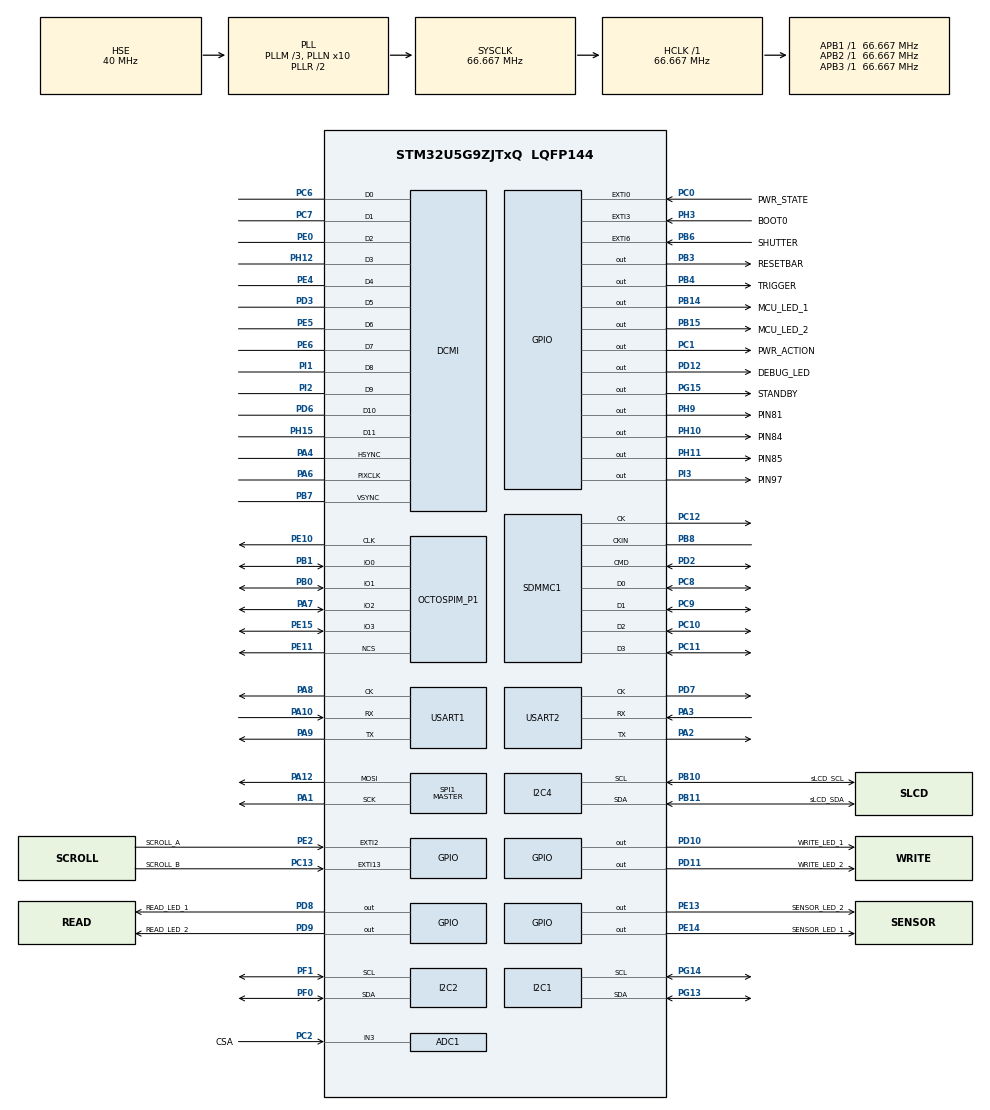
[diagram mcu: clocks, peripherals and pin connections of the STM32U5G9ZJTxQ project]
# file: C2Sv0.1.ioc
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ADC1.Channel-0\#ChannelRegularConversion=ADC_CHANNEL_3
ADC1.ContinuousConvMode=DISABLE
ADC1.MonitoredBy-0\#ChannelRegularConversion=__NULL
ADC1.NbrOfConversionFlag=1
ADC1.OffsetNumber-0\#ChannelRegularConversion=ADC_OFFSET_NONE
ADC1.Rank-0\#ChannelRegularConversion=1
ADC1.Resolution=ADC_RESOLUTION_14B
ADC1.SamplingTime-0\#ChannelRegularConversion=ADC_SAMPLETIME_5CYCLE
ADC1.master=1
CORTEX_M33_NS.userName=CORTEX_M33
DCMI.VSPolarity=DCMI_VSPOLARITY_HIGH
FILEX.FX_DRIVER_SDMMC_INIT=1
FILEX.FX_SD_INTERFACE=1
GPDMA1.IPHANDLE_GPDMACH11-SIMPLEREQUEST_GPDMACH11=__NULL
GPDMA1.PRIORITY_GPDMACH11=DMA_HIGH_PRIORITY
GPDMA1.RECAP_GPDMACH11=86
GPDMA1.REQUEST_GPDMACH11=GPDMA1_REQUEST_DCMI_PSSI
GPDMA1.SRCDATAWIDTH_GPDMACH11=DMA_SRC_DATAWIDTH_WORD
I2C1.Timing=0x108082C4
I2C2.Timing=0x108082C4
I2C4.Timing=0x108082C4
Mcu.Family=STM32U5
Mcu.Name=STM32U5G9ZJTxQ
Mcu.Package=LQFP144
NVIC.DCMI_PSSI_IRQn=true\:0\:0\:false\:false\:true\:true\:true\:true
NVIC.EXTI0_IRQn=true\:0\:0\:false\:false\:true\:true\:true\:true
NVIC.EXTI13_IRQn=true\:0\:0\:false\:false\:true\:true\:true\:true
NVIC.EXTI2_IRQn=true\:0\:0\:false\:false\:true\:true\:true\:true
NVIC.EXTI3_IRQn=true\:0\:0\:false\:false\:true\:true\:true\:true
NVIC.EXTI6_IRQn=true\:0\:0\:false\:false\:true\:true\:true\:true
NVIC.GPDMA1_Channel11_IRQn=true\:0\:0\:false\:false\:true\:false\:true\:true
NVIC.PriorityGroup=NVIC_PRIORITYGROUP_4
NVIC.SDMMC1_IRQn=true\:0\:0\:false\:false\:true\:true\:true\:true
OCTOSPI1.ChipSelectHighTime=3
OCTOSPI1.ClockPrescaler=5
OCTOSPI1.DeviceSize=24
OCTOSPI1.SampleShifting=HAL_OSPI_SAMPLE_SHIFTING_HALFCYCLE
PA1.Mode=TX_Only_Simplex_Unidirect_Master
PA1.Signal=SPI1_SCK
PA10.Mode=Synchronous
PA10.Signal=USART1_RX
PA12.Mode=TX_Only_Simplex_Unidirect_Master
PA12.Signal=SPI1_MOSI
PA13\ (JTMS/SWDIO).Mode=Serial_Wire
PA13\ (JTMS/SWDIO).Signal=DEBUG_JTMS-SWDIO
PA14\ (JTCK/SWCLK).Mode=Serial_Wire
PA14\ (JTCK/SWCLK).Signal=DEBUG_JTCK-SWCLK
PA2.Mode=Synchronous
PA2.Signal=USART2_TX
PA3.Mode=Synchronous
PA3.Signal=USART2_RX
PA4.GPIO_PuPd=GPIO_PULLDOWN
PA4.GPIO_Speed=GPIO_SPEED_FREQ_HIGH
PA4.Mode=Slave_12_bits_External_Synchro
PA4.Signal=DCMI_HSYNC
PA6.GPIO_PuPd=GPIO_PULLDOWN
PA6.GPIO_Speed=GPIO_SPEED_FREQ_HIGH
PA6.Mode=Slave_12_bits_External_Synchro
PA6.Signal=DCMI_PIXCLK
PA7.Mode=OCTOSPI1_IOL_Port1L
PA7.Signal=OCTOSPIM_P1_IO2
PA8.Mode=Synchronous
PA8.Signal=USART1_CK
PA9.Mode=Synchronous
PA9.Signal=USART1_TX
PB0.Mode=OCTOSPI1_IOL_Port1L
PB0.Signal=OCTOSPIM_P1_IO1
PB1.Mode=OCTOSPI1_IOL_Port1L
PB1.Signal=OCTOSPIM_P1_IO0
PB10.GPIO_Label=sLCD_SCL
PB10.Mode=I2C
PB10.Signal=I2C4_SCL
PB11.GPIO_Label=sLCD_SDA
PB11.Mode=I2C
PB11.Signal=I2C4_SDA
PB14.GPIO_Label=MCU_LED_1
PB14.Signal=GPIO_Output
PB15.GPIO_Label=MCU_LED_2
PB15.Signal=GPIO_Output
PB3\ (JTDO/TRACESWO).GPIO_Label=RESETBAR
PB3\ (JTDO/TRACESWO).GPIO_ModeDefaultOutputPP=GPIO_MODE_OUTPUT_OD
PB3\ (JTDO/TRACESWO).GPIO_PuPd=GPIO_NOPULL
PB3\ (JTDO/TRACESWO).PinState=GPIO_PIN_SET
PB3\ (JTDO/TRACESWO).Signal=GPIO_Output
PB4\ (NJTRST).GPIO_Label=TRIGGER
PB4\ (NJTRST).Signal=GPIO_Output
PB6.GPIO_Label=SHUTTER
PB6.GPIO_ModeDefaultEXTI=GPIO_MODE_IT_RISING_FALLING
PB6.Signal=GPXTI6
PB7.GPIO_PuPd=GPIO_PULLDOWN
PB7.GPIO_Speed=GPIO_SPEED_FREQ_HIGH
PB7.Mode=Slave_12_bits_External_Synchro
PB7.Signal=DCMI_VSYNC
PB8.GPIO_Speed_HighF_Default=GPIO_SPEED_FREQ_VERY_HIGH
PB8.Mode=SD_4_bits_Wide_bus_auto_dir_voltage_converter
PB8.Signal=SDMMC1_CKIN
PC0.GPIO_Label=PWR_STATE
PC0.GPIO_ModeDefaultEXTI=GPIO_MODE_IT_RISING
PC0.Signal=GPXTI0
PC1.GPIO_Label=PWR_ACTION
PC1.Signal=GPIO_Output
PC10.GPIO_Speed_HighF_Default=GPIO_SPEED_FREQ_VERY_HIGH
PC10.Mode=SD_4_bits_Wide_bus_auto_dir_voltage_converter
PC10.Signal=SDMMC1_D2
PC11.GPIO_Speed_HighF_Default=GPIO_SPEED_FREQ_VERY_HIGH
PC11.Mode=SD_4_bits_Wide_bus_auto_dir_voltage_converter
PC11.Signal=SDMMC1_D3
PC12.GPIO_Speed_HighF_Default=GPIO_SPEED_FREQ_VERY_HIGH
PC12.Mode=SD_4_bits_Wide_bus_auto_dir_voltage_converter
PC12.Signal=SDMMC1_CK
PC13.GPIO_Label=SCROLL_B
PC13.GPIO_ModeDefaultEXTI=GPIO_MODE_IT_RISING_FALLING
PC13.GPIO_PuPd=GPIO_PULLUP
PC13.Signal=GPXTI13
PC14-OSC32_IN\ (PC14).Mode=LSE-External-Clock-Source
PC14-OSC32_IN\ (PC14).Signal=RCC_OSC32_IN
PC2.GPIO_Label=CSA
PC2.GPIO_Pd=GPIO_PULLDOWN
PC2.Mode=IN3-Single-Ended
PC2.Signal=ADC1_IN3
PC6.GPIO_PuPd=GPIO_PULLDOWN
PC6.GPIO_Speed=GPIO_SPEED_FREQ_HIGH
PC6.Mode=Slave_12_bits_External_Synchro
PC6.Signal=DCMI_D0
PC7.GPIO_PuPd=GPIO_PULLDOWN
PC7.GPIO_Speed=GPIO_SPEED_FREQ_HIGH
PC7.Mode=Slave_12_bits_External_Synchro
PC7.Signal=DCMI_D1
PC8.GPIO_Speed_HighF_Default=GPIO_SPEED_FREQ_VERY_HIGH
PC8.Mode=SD_4_bits_Wide_bus_auto_dir_voltage_converter
PC8.Signal=SDMMC1_D0
PC9.GPIO_Speed_HighF_Default=GPIO_SPEED_FREQ_VERY_HIGH
PC9.Mode=SD_4_bits_Wide_bus_auto_dir_voltage_converter
PC9.Signal=SDMMC1_D1
PD10.GPIO_Label=WRITE_LED_1
PD10.Signal=GPIO_Output
PD11.GPIO_Label=WRITE_LED_2
PD11.Signal=GPIO_Output
PD12.GPIO_Label=DEBUG_LED
PD12.Signal=GPIO_Output
PD2.GPIO_Speed_HighF_Default=GPIO_SPEED_FREQ_VERY_HIGH
PD2.Mode=SD_4_bits_Wide_bus_auto_dir_voltage_converter
PD2.Signal=SDMMC1_CMD
PD3.GPIO_PuPd=GPIO_PULLDOWN
PD3.GPIO_Speed=GPIO_SPEED_FREQ_HIGH
PD3.Mode=Slave_12_bits_External_Synchro
PD3.Signal=DCMI_D5
PD6.GPIO_PuPd=GPIO_PULLDOWN
PD6.GPIO_Speed=GPIO_SPEED_FREQ_HIGH
PD6.Mode=Slave_12_bits_External_Synchro
PD6.Signal=DCMI_D10
PD7.Mode=Synchronous
PD7.Signal=USART2_CK
PD8.GPIO_Label=READ_LED_1
PD8.Signal=GPIO_Output
PD9.GPIO_Label=READ_LED_2
PD9.Signal=GPIO_Output
PE0.GPIO_PuPd=GPIO_PULLDOWN
PE0.GPIO_Speed=GPIO_SPEED_FREQ_HIGH
PE0.Mode=Slave_12_bits_External_Synchro
PE0.Signal=DCMI_D2
PE10.Mode=O1_P1_CLK
PE10.Signal=OCTOSPIM_P1_CLK
PE11.GPIO_PuPd=GPIO_PULLUP
PE11.Mode=OCTOSPI1_Port1_NCS
PE11.Signal=OCTOSPIM_P1_NCS
PE13.GPIO_Label=SENSOR_LED_2
PE13.Signal=GPIO_Output
PE14.GPIO_Label=SENSOR_LED_1
PE14.Signal=GPIO_Output
PE15.Mode=OCTOSPI1_IOL_Port1L
PE15.Signal=OCTOSPIM_P1_IO3
PE2.GPIO_Label=SCROLL_A
PE2.GPIO_ModeDefaultEXTI=GPIO_MODE_IT_RISING_FALLING
PE2.GPIO_PuPd=GPIO_PULLUP
PE2.Signal=GPXTI2
PE4.GPIO_PuPd=GPIO_PULLDOWN
PE4.GPIO_Speed=GPIO_SPEED_FREQ_HIGH
PE4.Mode=Slave_12_bits_External_Synchro
PE4.Signal=DCMI_D4
PE5.GPIO_PuPd=GPIO_PULLDOWN
PE5.GPIO_Speed=GPIO_SPEED_FREQ_HIGH
PE5.Mode=Slave_12_bits_External_Synchro
PE5.Signal=DCMI_D6
PE6.GPIO_PuPd=GPIO_PULLDOWN
PE6.GPIO_Speed=GPIO_SPEED_FREQ_HIGH
PE6.Mode=Slave_12_bits_External_Synchro
PE6.Signal=DCMI_D7
PF0.Mode=I2C
PF0.Signal=I2C2_SDA
PF1.Mode=I2C
PF1.Signal=I2C2_SCL
PG13.GPIO_Pu=GPIO_NOPULL
PG13.Mode=I2C
PG13.Signal=I2C1_SDA
PG14.Mode=I2C
PG14.Signal=I2C1_SCL
PG15.GPIO_Label=STANDBY
PG15.Signal=GPIO_Output
PH0-OSC_IN\ (PH0).Mode=HSE-External-Clock-Source
PH0-OSC_IN\ (PH0).Signal=RCC_OSC_IN
PH10.GPIO_Label=PIN84
PH10.Signal=GPIO_Output
PH11.GPIO_Label=PIN85
PH11.Signal=GPIO_Output
PH12.GPIO_PuPd=GPIO_PULLDOWN
PH12.GPIO_Speed=GPIO_SPEED_FREQ_HIGH
PH12.Mode=Slave_12_bits_External_Synchro
PH12.Signal=DCMI_D3
PH15.GPIO_PuPd=GPIO_PULLDOWN
PH15.GPIO_Speed=GPIO_SPEED_FREQ_HIGH
PH15.Mode=Slave_12_bits_External_Synchro
PH15.Signal=DCMI_D11
PH3-BOOT0.GPIO_Label=BOOT0
PH3-BOOT0.Signal=GPXTI3
PH9.GPIO_Label=PIN81
PH9.Signal=GPIO_Output
PI1.GPIO_PuPd=GPIO_PULLDOWN
PI1.GPIO_Speed=GPIO_SPEED_FREQ_HIGH
PI1.Mode=Slave_12_bits_External_Synchro
PI1.Signal=DCMI_D8
PI2.GPIO_PuPd=GPIO_PULLDOWN
PI2.GPIO_Speed=GPIO_SPEED_FREQ_HIGH
PI2.Mode=Slave_12_bits_External_Synchro
PI2.Signal=DCMI_D9
PI3.GPIO_Label=PIN97
PI3.Signal=GPIO_Output
ProjectManager.HeapSize=0x200
ProjectManager.StackSize=0x400
ProjectManager.TargetToolchain=STM32CubeIDE
RCC.ADCFreq_Value=16000000
RCC.AHBFreq_Value=66666666.66666667
RCC.APB1Freq_Value=66666666.66666667
RCC.APB1TimFreq_Value=66666666.66666667
RCC.APB2Freq_Value=66666666.66666667
RCC.APB2TimFreq_Value=66666666.66666667
RCC.APB3Freq_Value=66666666.66666667
RCC.CortexFreq_Value=66666666.66666667
RCC.EPOD_VALUE=40000000
RCC.HCLKFreq_Value=66666666.66666667
RCC.HSE_VALUE=40000000
RCC.HSI48_VALUE=48000000
RCC.HSI_VALUE=16000000
RCC.LSE_VALUE=32768
RCC.LSIDIV_VALUE=32000
RCC.MSI_VALUE=4000000
RCC.OCTOSPIMCLockSelection=RCC_OSPICLKSOURCE_PLL2
RCC.PLL1P=1
RCC.PLL2M=10
RCC.PLL2N=133
RCC.PLL2Q=4
RCC.PLL2Source=RCC_PLLSOURCE_HSE
RCC.PLLFRACN=0
RCC.PLLM=3
RCC.PLLN=10
RCC.PLLSourceVirtual=RCC_PLLSOURCE_HSE
RCC.RTCClockSelection=RCC_RTCCLKSOURCE_LSE
RCC.SDMMCClockSelection=RCC_SDMMCCLKSOURCE_CLK48
RCC.SYSCLKFreq_VALUE=66666666.66666667
RCC.SYSCLKSource=RCC_SYSCLKSOURCE_PLLCLK
RCC.VCOOutputFreq_Value=133333333.33333334
SDMMC1.ClockDiv=8
SPI1.CLKPhase=SPI_PHASE_2EDGE
SPI1.CLKPolarity=SPI_POLARITY_HIGH
SPI1.CalculateBaudRate=33.333332 MBits/s
SPI1.DataSize=SPI_DATASIZE_8BIT
SPI1.Direction=SPI_DIRECTION_2LINES_TXONLY
SPI1.Mode=SPI_MODE_MASTER
SPI1.VirtualType=VM_MASTER
USART1.VirtualMode-Synchronous=VM_SYNC
USART2.VirtualMode-Synchronous=VM_SYNC
VP_FILEX_VS_FileOoSystemJjFileXJjCore.Mode=FileX_Core
VP_FILEX_VS_SDOointerface.Mode=SD_interface
VP_GPDMA1_VS_GPDMACH11.Mode=SIMPLEREQUEST_GPDMACH11
VP_JPEG_VS_JPEG.Mode=JPEG_Activate
VP_LPBAMQUEUE_VS_QUEUE.Mode=QUEUEMODE
VP_LPBAM_VS_SIG1.Mode=SmartRun
VP_LPBAM_VS_SIG4.Mode=LPDMA1
VP_MEMORYMAP_VS_MEMORYMAP.Mode=CurAppReg
VP_OCTOSPI1_VS_quad.Mode=quad_mode
VP_PWR_VS_SECSignals.Mode=Security/Privilege
VP_PWR_Vdda.Mode=isolationVdda
VP_RTC_VS_RTC_Activate.Mode=RTC_Enabled
board=custom

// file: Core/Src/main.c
/* USER CODE BEGIN Header */
/**
  ******************************************************************************
  * @file           : main.c
  * @brief          : Main program body
  ******************************************************************************
  * @attention
  *
  * Copyright (c) 2025 STMicroelectronics.
  * All rights reserved.
  *
  * This software is licensed under terms that can be found in the LICENSE file
  * in the root directory of this software component.
  * If no LICENSE file comes with this software, it is provided AS-IS.
  *
  ******************************************************************************
  */
/* USER CODE END Header */
#include "main.h"
#include "jpeg_utils_conf.h"
#include "app_filex.h"
#include "jpeg_codec.h"
#include "test_image.h"

/* USER CODE BEGIN PD */

#define SAMPLE_PERIOD_MS 50
#define POWER_AVG_WINDOW_MS 1000

#define ENCODER_VAL scroll_encoder.cfg.arr[scroll_encoder.cfg.idx]

/* USER CODE END PD */

ADC_HandleTypeDef hadc1;

DCMI_HandleTypeDef hdcmi;
DMA_HandleTypeDef handle_GPDMA1_Channel11;

I2C_HandleTypeDef hi2c1;
I2C_HandleTypeDef hi2c2;
I2C_HandleTypeDef hi2c4;

JPEG_HandleTypeDef hjpeg;

OSPI_HandleTypeDef hospi1;

RTC_HandleTypeDef hrtc;

SD_HandleTypeDef hsd1;

SPI_HandleTypeDef hspi1;

USART_HandleTypeDef husart1;
USART_HandleTypeDef husart2;

/* USER CODE BEGIN PV */

// Scoll Encoder
Encoder_HandleTypeDef scroll_encoder;
int BOOT0 = 0;

// Current Sense Amplifier (CSA) Variables
CSA_HandleTypeDef csa;
uint32_t prevTime = 0;
float powerSum = 0;
float powerAvg = 0;
float currentSum = 0;
float voltageSum = 0;
float currentAvg = 0;
float voltageAvg = 0;
uint32_t sampleCount = 0;

// OCTOSPI
QSPI_HandleTypeDef QSPI_Memory;
QSPI_DataChunk_HandleTypeDef DataChunk;
OSPI_RegularCmdTypeDef sCommand;

// Image Sensor
uint16_t sensor_temp = 0;

#define JPEG_OUT_CAP (512 * 1024)
uint32_t jpeg_size = 0;
static uint8_t jpeg_out[JPEG_OUT_CAP];

/* USER CODE END PV */

void SystemClock_Config(void);
static void MX_GPIO_Init(void);
static void MX_GPDMA1_Init(void);
static void MX_ADC1_Init(void);
static void MX_I2C4_Init(void);
static void MX_OCTOSPI1_Init(void);
static void MX_SPI1_Init(void);
static void MX_I2C1_Init(void);
static void MX_JPEG_Init(void);
static void MX_DCMI_Init(void);
static void MX_I2C2_Init(void);
static void MX_USART1_Init(void);
static void MX_USART2_Init(void);
static void MX_RTC_Init(void);

int main(void)
{

  /* MCU Configuration--------------------------------------------------------*/

  /* Reset of all peripherals, Initializes the Flash interface and the Systick. */
  HAL_Init();

  /* Configure the system clock */
  SystemClock_Config();

  /* Initialize all configured peripherals */
  MX_GPIO_Init();
  MX_GPDMA1_Init();
  MX_ADC1_Init();
  MX_I2C4_Init();
  MX_OCTOSPI1_Init();
  MX_SPI1_Init();
  MX_I2C1_Init();
  MX_SDMMC1_SD_Init();
  MX_JPEG_Init();
  MX_DCMI_Init();
  MX_I2C2_Init();
  MX_USART1_Init();
  MX_USART2_Init();
  MX_FileX_Init();
  MX_RTC_Init();
  /* USER CODE BEGIN 2 */

  // Compatability Check
  if (VERIFY_CFG == 1) {
	  // compat check
  }

  // Initialise subsystems

// Image Sensor
	  JPEG_Encode_Gray(&hjpeg, test_image, 1024, 720, 30, jpeg_out, sizeof(jpeg_out), &jpeg_size);
	  uSD_Init();
	  SD_Stream_Data("testimg.jpg", jpeg_out, jpeg_size, 1);
//	  AR_Init_Temperature(&hi2c1);
//	  AR_Read_Temperature(&hi2c1, &sensor_temp);
//	  AR_Init_ImageSensor(&hi2c1);

  	  // Test microSD writing
//	  HAL_Delay(2000);
//	  Test_Image_Stream();

	  // Current Sense Amplifier
	  CSA_Init(&csa, SHUNT_RESISTANCE, 3.3f, 5.0f, 50);

	  // LEDs
	  LED_CONFIGURE_GND();

	  // Rotary Encoder
	  Encoder_Init(&scroll_encoder, SCROLL_A_GPIO_Port, SCROLL_A_Pin,
					   SCROLL_B_GPIO_Port, SCROLL_B_Pin);
	  // LCD Screen
	  if (SELECTED_LCD) { sLCD_Init(&hi2c4); }

	  // QSPI Memory
	  QSPI_Init_Memory(&hospi1, &sCommand, &QSPI_Memory);

	  // OCTOSPI
//	  QSPI_Init_DataBlock(&DataChunk, sizeof(tx_str), tx_str, rx_str);
//	  QSPI_Write_Data(&QSPI_Memory, &DataChunk);
//	  QSPI_Read_Data(&QSPI_Memory, &DataChunk);
//	  QSPI_Erase_Data(&QSPI_Memory, &DataChunk);

  /* USER CODE END 2 */

  /* Infinite loop */
  /* USER CODE BEGIN WHILE */
  while (1)
  {
	  // Update LEDs
	  LED_SyncEncoder(ENCODER_VAL);

	  // Update and get CSA voltage
	  CSA_Update(&csa, &hadc1);

	  // Delay
	  HAL_Delay(SAMPLE_PERIOD_MS);

	  // Read BOOT0 Pin State
	  BOOT0 = HAL_GPIO_ReadPin(BOOT0_GPIO_Port, BOOT0_Pin);

	  powerSum   += csa.sys_power;
	  currentSum += csa.current;
	  voltageSum += csa.voltage;
	  sampleCount++; // Track real number of samples

	  uint32_t now = HAL_GetTick();
	  if ((now - prevTime) >= POWER_AVG_WINDOW_MS && sampleCount > 0) {
	      // Use 64-bit math to prevent overflow and maintain precision
	      powerAvg   = (uint32_t)((powerSum * 1000) / sampleCount);
	      currentAvg = (uint32_t)((currentSum * 1000) / sampleCount);
	      voltageAvg = (uint32_t)((voltageSum * 1000) / sampleCount);

	      // Reset
	      powerSum = 0; currentSum = 0; voltageSum = 0;
	      sampleCount = 0;
	      prevTime = now;
	  }

	  float lcd_vals[3] = {powerAvg, currentAvg, voltageAvg};
	  if (SELECTED_LCD) { sLCD_CSA_DISPLAY(scroll_encoder.cfg.idx, lcd_vals); }

    /* USER CODE END WHILE */

  }
}

void SystemClock_Config(void)
{
  RCC_OscInitTypeDef RCC_OscInitStruct = {0};
  RCC_ClkInitTypeDef RCC_ClkInitStruct = {0};

  /** Configure the main internal regulator output voltage
  */
  if (HAL_PWREx_ControlVoltageScaling(PWR_REGULATOR_VOLTAGE_SCALE2) != HAL_OK)
  {
    Error_Handler();
  }

  /** Initializes the CPU, AHB and APB buses clocks
  */
  RCC_OscInitStruct.OscillatorType = RCC_OSCILLATORTYPE_HSI48|RCC_OSCILLATORTYPE_HSI
                              |RCC_OSCILLATORTYPE_HSE|RCC_OSCILLATORTYPE_LSE;
  RCC_OscInitStruct.HSEState = RCC_HSE_BYPASS;
  RCC_OscInitStruct.LSEState = RCC_LSE_BYPASS;
  RCC_OscInitStruct.HSIState = RCC_HSI_ON;
  RCC_OscInitStruct.HSI48State = RCC_HSI48_ON;
  RCC_OscInitStruct.HSICalibrationValue = RCC_HSICALIBRATION_DEFAULT;
  RCC_OscInitStruct.PLL.PLLState = RCC_PLL_ON;
  RCC_OscInitStruct.PLL.PLLSource = RCC_PLLSOURCE_HSE;
  RCC_OscInitStruct.PLL.PLLMBOOST = RCC_PLLMBOOST_DIV4;
  RCC_OscInitStruct.PLL.PLLM = 3;
  RCC_OscInitStruct.PLL.PLLN = 10;
  RCC_OscInitStruct.PLL.PLLP = 1;
  RCC_OscInitStruct.PLL.PLLQ = 2;
  RCC_OscInitStruct.PLL.PLLR = 2;
  RCC_OscInitStruct.PLL.PLLRGE = RCC_PLLVCIRANGE_1;
  RCC_OscInitStruct.PLL.PLLFRACN = 0;
  if (HAL_RCC_OscConfig(&RCC_OscInitStruct) != HAL_OK)
  {
    Error_Handler();
  }

  /** Initializes the CPU, AHB and APB buses clocks
  */
  RCC_ClkInitStruct.ClockType = RCC_CLOCKTYPE_HCLK|RCC_CLOCKTYPE_SYSCLK
                              |RCC_CLOCKTYPE_PCLK1|RCC_CLOCKTYPE_PCLK2
                              |RCC_CLOCKTYPE_PCLK3;
  RCC_ClkInitStruct.SYSCLKSource = RCC_SYSCLKSOURCE_PLLCLK;
  RCC_ClkInitStruct.AHBCLKDivider = RCC_SYSCLK_DIV1;
  RCC_ClkInitStruct.APB1CLKDivider = RCC_HCLK_DIV1;
  RCC_ClkInitStruct.APB2CLKDivider = RCC_HCLK_DIV1;
  RCC_ClkInitStruct.APB3CLKDivider = RCC_HCLK_DIV1;

  if (HAL_RCC_ClockConfig(&RCC_ClkInitStruct, FLASH_LATENCY_2) != HAL_OK)
  {
    Error_Handler();
  }
}

static void MX_ADC1_Init(void)
{

  ADC_ChannelConfTypeDef sConfig = {0};

  /** Common config
  */
  hadc1.Instance = ADC1;
  hadc1.Init.ClockPrescaler = ADC_CLOCK_ASYNC_DIV1;
  hadc1.Init.Resolution = ADC_RESOLUTION_14B;
  hadc1.Init.GainCompensation = 0;
  hadc1.Init.DataAlign = ADC_DATAALIGN_RIGHT;
  hadc1.Init.ScanConvMode = ADC_SCAN_DISABLE;
  hadc1.Init.EOCSelection = ADC_EOC_SINGLE_CONV;
  hadc1.Init.LowPowerAutoWait = DISABLE;
  hadc1.Init.ContinuousConvMode = DISABLE;
  hadc1.Init.NbrOfConversion = 1;
  hadc1.Init.DiscontinuousConvMode = DISABLE;
  hadc1.Init.ExternalTrigConv = ADC_SOFTWARE_START;
  hadc1.Init.ExternalTrigConvEdge = ADC_EXTERNALTRIGCONVEDGE_NONE;
  hadc1.Init.DMAContinuousRequests = DISABLE;
  hadc1.Init.TriggerFrequencyMode = ADC_TRIGGER_FREQ_HIGH;
  hadc1.Init.Overrun = ADC_OVR_DATA_PRESERVED;
  hadc1.Init.LeftBitShift = ADC_LEFTBITSHIFT_NONE;
  hadc1.Init.ConversionDataManagement = ADC_CONVERSIONDATA_DR;
  hadc1.Init.OversamplingMode = DISABLE;
  if (HAL_ADC_Init(&hadc1) != HAL_OK)
  {
    Error_Handler();
  }

  /** Configure Regular Channel
  */
  sConfig.Channel = ADC_CHANNEL_3;
  sConfig.Rank = ADC_REGULAR_RANK_1;
  sConfig.SamplingTime = ADC_SAMPLETIME_5CYCLE;
  sConfig.SingleDiff = ADC_SINGLE_ENDED;
  sConfig.OffsetNumber = ADC_OFFSET_NONE;
  sConfig.Offset = 0;
  if (HAL_ADC_ConfigChannel(&hadc1, &sConfig) != HAL_OK)
  {
    Error_Handler();
  }

}

static void MX_DCMI_Init(void)
{

  hdcmi.Instance = DCMI;
  hdcmi.Init.SynchroMode = DCMI_SYNCHRO_HARDWARE;
  hdcmi.Init.PCKPolarity = DCMI_PCKPOLARITY_FALLING;
  hdcmi.Init.VSPolarity = DCMI_VSPOLARITY_HIGH;
  hdcmi.Init.HSPolarity = DCMI_HSPOLARITY_LOW;
  hdcmi.Init.CaptureRate = DCMI_CR_ALL_FRAME;
  hdcmi.Init.ExtendedDataMode = DCMI_EXTEND_DATA_12B;
  hdcmi.Init.JPEGMode = DCMI_JPEG_DISABLE;
  hdcmi.Init.ByteSelectMode = DCMI_BSM_ALL;
  hdcmi.Init.ByteSelectStart = DCMI_OEBS_ODD;
  hdcmi.Init.LineSelectMode = DCMI_LSM_ALL;
  hdcmi.Init.LineSelectStart = DCMI_OELS_ODD;
  if (HAL_DCMI_Init(&hdcmi) != HAL_OK)
  {
    Error_Handler();
  }

}

static void MX_GPDMA1_Init(void)
{

  /* Peripheral clock enable */
  __HAL_RCC_GPDMA1_CLK_ENABLE();

  /* GPDMA1 interrupt Init */
    HAL_NVIC_SetPriority(GPDMA1_Channel11_IRQn, 0, 0);
    HAL_NVIC_EnableIRQ(GPDMA1_Channel11_IRQn);

}

static void MX_I2C1_Init(void)
{

  hi2c1.Instance = I2C1;
  hi2c1.Init.Timing = 0x108082C4;
  hi2c1.Init.OwnAddress1 = 0;
  hi2c1.Init.AddressingMode = I2C_ADDRESSINGMODE_7BIT;
  hi2c1.Init.DualAddressMode = I2C_DUALADDRESS_DISABLE;
  hi2c1.Init.OwnAddress2 = 0;
  hi2c1.Init.OwnAddress2Masks = I2C_OA2_NOMASK;
  hi2c1.Init.GeneralCallMode = I2C_GENERALCALL_DISABLE;
  hi2c1.Init.NoStretchMode = I2C_NOSTRETCH_DISABLE;
  if (HAL_I2C_Init(&hi2c1) != HAL_OK)
  {
    Error_Handler();
  }

  /** Configure Analogue filter
  */
  if (HAL_I2CEx_ConfigAnalogFilter(&hi2c1, I2C_ANALOGFILTER_ENABLE) != HAL_OK)
  {
    Error_Handler();
  }

  /** Configure Digital filter
  */
  if (HAL_I2CEx_ConfigDigitalFilter(&hi2c1, 0) != HAL_OK)
  {
    Error_Handler();
  }

}

static void MX_I2C2_Init(void)
{

  hi2c2.Instance = I2C2;
  hi2c2.Init.Timing = 0x108082C4;
  hi2c2.Init.OwnAddress1 = 0;
  hi2c2.Init.AddressingMode = I2C_ADDRESSINGMODE_7BIT;
  hi2c2.Init.DualAddressMode = I2C_DUALADDRESS_DISABLE;
  hi2c2.Init.OwnAddress2 = 0;
  hi2c2.Init.OwnAddress2Masks = I2C_OA2_NOMASK;
  hi2c2.Init.GeneralCallMode = I2C_GENERALCALL_DISABLE;
  hi2c2.Init.NoStretchMode = I2C_NOSTRETCH_DISABLE;
  if (HAL_I2C_Init(&hi2c2) != HAL_OK)
  {
    Error_Handler();
  }

  /** Configure Analogue filter
  */
  if (HAL_I2CEx_ConfigAnalogFilter(&hi2c2, I2C_ANALOGFILTER_ENABLE) != HAL_OK)
  {
    Error_Handler();
  }

  /** Configure Digital filter
  */
  if (HAL_I2CEx_ConfigDigitalFilter(&hi2c2, 0) != HAL_OK)
  {
    Error_Handler();
  }

}

static void MX_I2C4_Init(void)
{

  hi2c4.Instance = I2C4;
  hi2c4.Init.Timing = 0x108082C4;
  hi2c4.Init.OwnAddress1 = 0;
  hi2c4.Init.AddressingMode = I2C_ADDRESSINGMODE_7BIT;
  hi2c4.Init.DualAddressMode = I2C_DUALADDRESS_DISABLE;
  hi2c4.Init.OwnAddress2 = 0;
  hi2c4.Init.OwnAddress2Masks = I2C_OA2_NOMASK;
  hi2c4.Init.GeneralCallMode = I2C_GENERALCALL_DISABLE;
  hi2c4.Init.NoStretchMode = I2C_NOSTRETCH_DISABLE;
  if (HAL_I2C_Init(&hi2c4) != HAL_OK)
  {
    Error_Handler();
  }

  /** Configure Analogue filter
  */
  if (HAL_I2CEx_ConfigAnalogFilter(&hi2c4, I2C_ANALOGFILTER_ENABLE) != HAL_OK)
  {
    Error_Handler();
  }

  /** Configure Digital filter
  */
  if (HAL_I2CEx_ConfigDigitalFilter(&hi2c4, 0) != HAL_OK)
  {
    Error_Handler();
  }

}

static void MX_JPEG_Init(void)
{

  hjpeg.Instance = JPEG;
  if (HAL_JPEG_Init(&hjpeg) != HAL_OK)
  {
    Error_Handler();
  }

}

static void MX_OCTOSPI1_Init(void)
{

  OSPIM_CfgTypeDef sOspiManagerCfg = {0};

  /* OCTOSPI1 parameter configuration*/
  hospi1.Instance = OCTOSPI1;
  hospi1.Init.FifoThreshold = 1;
  hospi1.Init.DualQuad = HAL_OSPI_DUALQUAD_DISABLE;
  hospi1.Init.MemoryType = HAL_OSPI_MEMTYPE_MICRON;
  hospi1.Init.DeviceSize = 24;
  hospi1.Init.ChipSelectHighTime = 3;
  hospi1.Init.FreeRunningClock = HAL_OSPI_FREERUNCLK_DISABLE;
  hospi1.Init.ClockMode = HAL_OSPI_CLOCK_MODE_0;
  hospi1.Init.WrapSize = HAL_OSPI_WRAP_NOT_SUPPORTED;
  hospi1.Init.ClockPrescaler = 5;
  hospi1.Init.SampleShifting = HAL_OSPI_SAMPLE_SHIFTING_HALFCYCLE;
  hospi1.Init.DelayHoldQuarterCycle = HAL_OSPI_DHQC_DISABLE;
  hospi1.Init.ChipSelectBoundary = 0;
  hospi1.Init.DelayBlockBypass = HAL_OSPI_DELAY_BLOCK_BYPASSED;
  hospi1.Init.MaxTran = 0;
  hospi1.Init.Refresh = 0;
  if (HAL_OSPI_Init(&hospi1) != HAL_OK)
  {
    Error_Handler();
  }
  sOspiManagerCfg.ClkPort = 1;
  sOspiManagerCfg.NCSPort = 1;
  sOspiManagerCfg.IOLowPort = HAL_OSPIM_IOPORT_1_LOW;
  if (HAL_OSPIM_Config(&hospi1, &sOspiManagerCfg, HAL_OSPI_TIMEOUT_DEFAULT_VALUE) != HAL_OK)
  {
    Error_Handler();
  }

}

static void MX_RTC_Init(void)
{

  RTC_PrivilegeStateTypeDef privilegeState = {0};

  /** Initialize RTC Only
  */
  hrtc.Instance = RTC;
  hrtc.Init.HourFormat = RTC_HOURFORMAT_24;
  hrtc.Init.AsynchPrediv = 127;
  hrtc.Init.SynchPrediv = 255;
  hrtc.Init.OutPut = RTC_OUTPUT_DISABLE;
  hrtc.Init.OutPutRemap = RTC_OUTPUT_REMAP_NONE;
  hrtc.Init.OutPutPolarity = RTC_OUTPUT_POLARITY_HIGH;
  hrtc.Init.OutPutType = RTC_OUTPUT_TYPE_OPENDRAIN;
  hrtc.Init.OutPutPullUp = RTC_OUTPUT_PULLUP_NONE;
  hrtc.Init.BinMode = RTC_BINARY_NONE;
  if (HAL_RTC_Init(&hrtc) != HAL_OK)
  {
    Error_Handler();
  }
  privilegeState.rtcPrivilegeFull = RTC_PRIVILEGE_FULL_NO;
  privilegeState.backupRegisterPrivZone = RTC_PRIVILEGE_BKUP_ZONE_NONE;
  privilegeState.backupRegisterStartZone2 = RTC_BKP_DR0;
  privilegeState.backupRegisterStartZone3 = RTC_BKP_DR0;
  if (HAL_RTCEx_PrivilegeModeSet(&hrtc, &privilegeState) != HAL_OK)
  {
    Error_Handler();
  }

}

void MX_SDMMC1_SD_Init(void)
{

  hsd1.Instance = SDMMC1;
  hsd1.Init.ClockEdge = SDMMC_CLOCK_EDGE_RISING;
  hsd1.Init.ClockPowerSave = SDMMC_CLOCK_POWER_SAVE_DISABLE;
  hsd1.Init.BusWide = SDMMC_BUS_WIDE_4B;
  hsd1.Init.HardwareFlowControl = SDMMC_HARDWARE_FLOW_CONTROL_DISABLE;
  hsd1.Init.ClockDiv = 8;
  if (HAL_SD_Init(&hsd1) != HAL_OK)
  {
    Error_Handler();
  }

}

static void MX_SPI1_Init(void)
{

  SPI_AutonomousModeConfTypeDef HAL_SPI_AutonomousMode_Cfg_Struct = {0};

  /* SPI1 parameter configuration*/
  hspi1.Instance = SPI1;
  hspi1.Init.Mode = SPI_MODE_MASTER;
  hspi1.Init.Direction = SPI_DIRECTION_2LINES_TXONLY;
  hspi1.Init.DataSize = SPI_DATASIZE_8BIT;
  hspi1.Init.CLKPolarity = SPI_POLARITY_HIGH;
  hspi1.Init.CLKPhase = SPI_PHASE_2EDGE;
  hspi1.Init.NSS = SPI_NSS_SOFT;
  hspi1.Init.BaudRatePrescaler = SPI_BAUDRATEPRESCALER_2;
  hspi1.Init.FirstBit = SPI_FIRSTBIT_MSB;
  hspi1.Init.TIMode = SPI_TIMODE_DISABLE;
  hspi1.Init.CRCCalculation = SPI_CRCCALCULATION_DISABLE;
  hspi1.Init.CRCPolynomial = 0x7;
  hspi1.Init.NSSPMode = SPI_NSS_PULSE_DISABLE;
  hspi1.Init.NSSPolarity = SPI_NSS_POLARITY_LOW;
  hspi1.Init.FifoThreshold = SPI_FIFO_THRESHOLD_01DATA;
  hspi1.Init.MasterSSIdleness = SPI_MASTER_SS_IDLENESS_00CYCLE;
  hspi1.Init.MasterInterDataIdleness = SPI_MASTER_INTERDATA_IDLENESS_00CYCLE;
  hspi1.Init.MasterReceiverAutoSusp = SPI_MASTER_RX_AUTOSUSP_DISABLE;
  hspi1.Init.MasterKeepIOState = SPI_MASTER_KEEP_IO_STATE_DISABLE;
  hspi1.Init.IOSwap = SPI_IO_SWAP_DISABLE;
  hspi1.Init.ReadyMasterManagement = SPI_RDY_MASTER_MANAGEMENT_INTERNALLY;
  hspi1.Init.ReadyPolarity = SPI_RDY_POLARITY_HIGH;
  if (HAL_SPI_Init(&hspi1) != HAL_OK)
  {
    Error_Handler();
  }
  HAL_SPI_AutonomousMode_Cfg_Struct.TriggerState = SPI_AUTO_MODE_DISABLE;
  HAL_SPI_AutonomousMode_Cfg_Struct.TriggerSelection = SPI_GRP1_GPDMA_CH0_TCF_TRG;
  HAL_SPI_AutonomousMode_Cfg_Struct.TriggerPolarity = SPI_TRIG_POLARITY_RISING;
  if (HAL_SPIEx_SetConfigAutonomousMode(&hspi1, &HAL_SPI_AutonomousMode_Cfg_Struct) != HAL_OK)
  {
    Error_Handler();
  }

}

static void MX_USART1_Init(void)
{

  husart1.Instance = USART1;
  husart1.Init.BaudRate = 115200;
  husart1.Init.WordLength = USART_WORDLENGTH_8B;
  husart1.Init.StopBits = USART_STOPBITS_1;
  husart1.Init.Parity = USART_PARITY_NONE;
  husart1.Init.Mode = USART_MODE_TX_RX;
  husart1.Init.CLKPolarity = USART_POLARITY_LOW;
  husart1.Init.CLKPhase = USART_PHASE_1EDGE;
  husart1.Init.CLKLastBit = USART_LASTBIT_DISABLE;
  husart1.Init.ClockPrescaler = USART_PRESCALER_DIV1;
  husart1.SlaveMode = USART_SLAVEMODE_DISABLE;
  if (HAL_USART_Init(&husart1) != HAL_OK)
  {
    Error_Handler();
  }
  if (HAL_USARTEx_SetTxFifoThreshold(&husart1, USART_TXFIFO_THRESHOLD_1_8) != HAL_OK)
  {
    Error_Handler();
  }
  if (HAL_USARTEx_SetRxFifoThreshold(&husart1, USART_RXFIFO_THRESHOLD_1_8) != HAL_OK)
  {
    Error_Handler();
  }
  if (HAL_USARTEx_DisableFifoMode(&husart1) != HAL_OK)
  {
    Error_Handler();
  }

}

static void MX_USART2_Init(void)
{

  husart2.Instance = USART2;
  husart2.Init.BaudRate = 115200;
  husart2.Init.WordLength = USART_WORDLENGTH_8B;
  husart2.Init.StopBits = USART_STOPBITS_1;
  husart2.Init.Parity = USART_PARITY_NONE;
  husart2.Init.Mode = USART_MODE_TX_RX;
  husart2.Init.CLKPolarity = USART_POLARITY_LOW;
  husart2.Init.CLKPhase = USART_PHASE_1EDGE;
  husart2.Init.CLKLastBit = USART_LASTBIT_DISABLE;
  husart2.Init.ClockPrescaler = USART_PRESCALER_DIV1;
  husart2.SlaveMode = USART_SLAVEMODE_DISABLE;
  if (HAL_USART_Init(&husart2) != HAL_OK)
  {
    Error_Handler();
  }
  if (HAL_USARTEx_SetTxFifoThreshold(&husart2, USART_TXFIFO_THRESHOLD_1_8) != HAL_OK)
  {
    Error_Handler();
  }
  if (HAL_USARTEx_SetRxFifoThreshold(&husart2, USART_RXFIFO_THRESHOLD_1_8) != HAL_OK)
  {
    Error_Handler();
  }
  if (HAL_USARTEx_DisableFifoMode(&husart2) != HAL_OK)
  {
    Error_Handler();
  }

}

static void MX_GPIO_Init(void)
{
  GPIO_InitTypeDef GPIO_InitStruct = {0};

  /* GPIO Ports Clock Enable */
  __HAL_RCC_GPIOE_CLK_ENABLE();
  __HAL_RCC_GPIOC_CLK_ENABLE();
  __HAL_RCC_GPIOF_CLK_ENABLE();
  __HAL_RCC_GPIOH_CLK_ENABLE();
  __HAL_RCC_GPIOA_CLK_ENABLE();
  __HAL_RCC_GPIOB_CLK_ENABLE();
  __HAL_RCC_GPIOD_CLK_ENABLE();
  __HAL_RCC_GPIOI_CLK_ENABLE();
  __HAL_RCC_GPIOG_CLK_ENABLE();

  /*Configure GPIO pin Output Level */
  HAL_GPIO_WritePin(PWR_ACTION_GPIO_Port, PWR_ACTION_Pin, GPIO_PIN_RESET);

  /*Configure GPIO pin Output Level */
  HAL_GPIO_WritePin(GPIOE, SENSOR_LED_2_Pin|SENSOR_LED_1_Pin, GPIO_PIN_RESET);

  /*Configure GPIO pin Output Level */
  HAL_GPIO_WritePin(GPIOB, MCU_LED_1_Pin|MCU_LED_2_Pin|TRIGGER_Pin, GPIO_PIN_RESET);

  /*Configure GPIO pin Output Level */
  HAL_GPIO_WritePin(GPIOD, READ_LED_1_Pin|READ_LED_2_Pin|WRITE_LED_1_Pin|WRITE_LED_2_Pin
                          |DEBUG_LED_Pin, GPIO_PIN_RESET);

  /*Configure GPIO pin Output Level */
  HAL_GPIO_WritePin(GPIOH, PIN81_Pin|PIN84_Pin|PIN85_Pin, GPIO_PIN_RESET);

  /*Configure GPIO pin Output Level */
  HAL_GPIO_WritePin(PIN97_GPIO_Port, PIN97_Pin, GPIO_PIN_RESET);

  /*Configure GPIO pin Output Level */
  HAL_GPIO_WritePin(STANDBY_GPIO_Port, STANDBY_Pin, GPIO_PIN_RESET);

  /*Configure GPIO pin Output Level */
  HAL_GPIO_WritePin(RESETBAR_GPIO_Port, RESETBAR_Pin, GPIO_PIN_SET);

  /*Configure GPIO pin : SCROLL_A_Pin */
  GPIO_InitStruct.Pin = SCROLL_A_Pin;
  GPIO_InitStruct.Mode = GPIO_MODE_IT_RISING_FALLING;
  GPIO_InitStruct.Pull = GPIO_PULLUP;
  HAL_GPIO_Init(SCROLL_A_GPIO_Port, &GPIO_InitStruct);

  /*Configure GPIO pin : SCROLL_B_Pin */
  GPIO_InitStruct.Pin = SCROLL_B_Pin;
  GPIO_InitStruct.Mode = GPIO_MODE_IT_RISING_FALLING;
  GPIO_InitStruct.Pull = GPIO_PULLUP;
  HAL_GPIO_Init(SCROLL_B_GPIO_Port, &GPIO_InitStruct);

  /*Configure GPIO pin : PWR_STATE_Pin */
  GPIO_InitStruct.Pin = PWR_STATE_Pin;
  GPIO_InitStruct.Mode = GPIO_MODE_IT_RISING;
  GPIO_InitStruct.Pull = GPIO_NOPULL;
  HAL_GPIO_Init(PWR_STATE_GPIO_Port, &GPIO_InitStruct);

  /*Configure GPIO pin : PWR_ACTION_Pin */
  GPIO_InitStruct.Pin = PWR_ACTION_Pin;
  GPIO_InitStruct.Mode = GPIO_MODE_OUTPUT_PP;
  GPIO_InitStruct.Pull = GPIO_NOPULL;
  GPIO_InitStruct.Speed = GPIO_SPEED_FREQ_LOW;
  HAL_GPIO_Init(PWR_ACTION_GPIO_Port, &GPIO_InitStruct);

  /*Configure GPIO pins : SENSOR_LED_2_Pin SENSOR_LED_1_Pin */
  GPIO_InitStruct.Pin = SENSOR_LED_2_Pin|SENSOR_LED_1_Pin;
  GPIO_InitStruct.Mode = GPIO_MODE_OUTPUT_PP;
  GPIO_InitStruct.Pull = GPIO_NOPULL;
  GPIO_InitStruct.Speed = GPIO_SPEED_FREQ_LOW;
  HAL_GPIO_Init(GPIOE, &GPIO_InitStruct);

  /*Configure GPIO pins : MCU_LED_1_Pin MCU_LED_2_Pin TRIGGER_Pin */
  GPIO_InitStruct.Pin = MCU_LED_1_Pin|MCU_LED_2_Pin|TRIGGER_Pin;
  GPIO_InitStruct.Mode = GPIO_MODE_OUTPUT_PP;
  GPIO_InitStruct.Pull = GPIO_NOPULL;
  GPIO_InitStruct.Speed = GPIO_SPEED_FREQ_LOW;
  HAL_GPIO_Init(GPIOB, &GPIO_InitStruct);

  /*Configure GPIO pins : READ_LED_1_Pin READ_LED_2_Pin WRITE_LED_1_Pin WRITE_LED_2_Pin
                           DEBUG_LED_Pin */
  GPIO_InitStruct.Pin = READ_LED_1_Pin|READ_LED_2_Pin|WRITE_LED_1_Pin|WRITE_LED_2_Pin
                          |DEBUG_LED_Pin;
  GPIO_InitStruct.Mode = GPIO_MODE_OUTPUT_PP;
  GPIO_InitStruct.Pull = GPIO_NOPULL;
  GPIO_InitStruct.Speed = GPIO_SPEED_FREQ_LOW;
  HAL_GPIO_Init(GPIOD, &GPIO_InitStruct);

  /*Configure GPIO pins : PIN81_Pin PIN84_Pin PIN85_Pin */
  GPIO_InitStruct.Pin = PIN81_Pin|PIN84_Pin|PIN85_Pin;
  GPIO_InitStruct.Mode = GPIO_MODE_OUTPUT_PP;
  GPIO_InitStruct.Pull = GPIO_NOPULL;
  GPIO_InitStruct.Speed = GPIO_SPEED_FREQ_LOW;
  HAL_GPIO_Init(GPIOH, &GPIO_InitStruct);

  /*Configure GPIO pin : PIN97_Pin */
  GPIO_InitStruct.Pin = PIN97_Pin;
  GPIO_InitStruct.Mode = GPIO_MODE_OUTPUT_PP;
  GPIO_InitStruct.Pull = GPIO_NOPULL;
  GPIO_InitStruct.Speed = GPIO_SPEED_FREQ_LOW;
  HAL_GPIO_Init(PIN97_GPIO_Port, &GPIO_InitStruct);

  /*Configure GPIO pin : STANDBY_Pin */
  GPIO_InitStruct.Pin = STANDBY_Pin;
  GPIO_InitStruct.Mode = GPIO_MODE_OUTPUT_PP;
  GPIO_InitStruct.Pull = GPIO_NOPULL;
  GPIO_InitStruct.Speed = GPIO_SPEED_FREQ_LOW;
  HAL_GPIO_Init(STANDBY_GPIO_Port, &GPIO_InitStruct);

  /*Configure GPIO pin : RESETBAR_Pin */
  GPIO_InitStruct.Pin = RESETBAR_Pin;
  GPIO_InitStruct.Mode = GPIO_MODE_OUTPUT_OD;
  GPIO_InitStruct.Pull = GPIO_NOPULL;
  GPIO_InitStruct.Speed = GPIO_SPEED_FREQ_LOW;
  HAL_GPIO_Init(RESETBAR_GPIO_Port, &GPIO_InitStruct);

  /*Configure GPIO pin : SHUTTER_Pin */
  GPIO_InitStruct.Pin = SHUTTER_Pin;
  GPIO_InitStruct.Mode = GPIO_MODE_IT_RISING_FALLING;
  GPIO_InitStruct.Pull = GPIO_NOPULL;
  HAL_GPIO_Init(SHUTTER_GPIO_Port, &GPIO_InitStruct);

  /*Configure GPIO pin : BOOT0_Pin */
  GPIO_InitStruct.Pin = BOOT0_Pin;
  GPIO_InitStruct.Mode = GPIO_MODE_IT_RISING;
  GPIO_InitStruct.Pull = GPIO_NOPULL;
  HAL_GPIO_Init(BOOT0_GPIO_Port, &GPIO_InitStruct);

  /* EXTI interrupt init*/
  HAL_NVIC_SetPriority(EXTI0_IRQn, 0, 0);
  HAL_NVIC_EnableIRQ(EXTI0_IRQn);

  HAL_NVIC_SetPriority(EXTI2_IRQn, 0, 0);
  HAL_NVIC_EnableIRQ(EXTI2_IRQn);

  HAL_NVIC_SetPriority(EXTI3_IRQn, 0, 0);
  HAL_NVIC_EnableIRQ(EXTI3_IRQn);

  HAL_NVIC_SetPriority(EXTI6_IRQn, 0, 0);
  HAL_NVIC_EnableIRQ(EXTI6_IRQn);

  HAL_NVIC_SetPriority(EXTI13_IRQn, 0, 0);
  HAL_NVIC_EnableIRQ(EXTI13_IRQn);

}

void Error_Handler(void)
{
  __disable_irq();
  while (1)
  {
  }
}
